# CEC1712H_S2_SX register map
Vendor: Microchip
Registers are 32-bit, read-write, reset 0x0 unless marked. A register's access mark holds for its fields unless they carry their own. Addresses are absolute, and some are shared; only a register's first bit layout is shown; [hi:lo] are bit positions; {n}, {i} and the like mark numbered series; 'fields as' and 'values as' point back to an identical list.

## GPIO
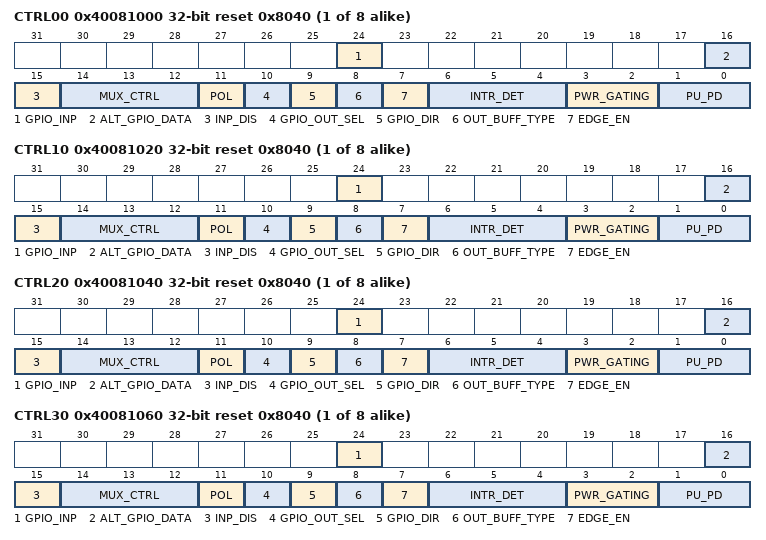
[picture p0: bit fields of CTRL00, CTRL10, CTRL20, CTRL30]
{0x40081000+4i} CTRL{i:02} reset 0x8040 (i=0..7)
  [24] GPIO_INP — GPIO input from pin, independent of the Mux selection for the pin or the Direction.
  [16] ALT_GPIO_DATA — GPIO Alternate Data Register.
  [15] INP_DIS — GPIO input disable
  [14:12] MUX_CTRL — 00 = GPIO Function, 01 = Function 1, 10 = Function 2, 11 = Function 3.
  [11] POL — 1=Inverted; 0=Non-inverted
  [10] GPIO_OUT_SEL — GPIO outputs registe select.0=GPIO ALTERNATE_GPIO_DATA 1=GPIO Output Register.
  [9] GPIO_DIR — Buffer direction when GPIO selected by pin mux 0 = Input, 1 = Output
  [8] OUT_BUFF_TYPE — 0 = Push-Pull, 1 = Open Drain
  [7] EDGE_EN — Determines the interrupt capability of the GPIO input.
  [6:4] INTR_DET — Determines the interrupt capability of the GPIO input.
  [3:2] PWR_GATING — The GPIO pin will be tristated when the selected power well is off.
  [1:0] PU_PD — These bits are used to enable an internal pull-up or pull-down resistor.
{0x40080FF8+4i} CTRL{i} reset 0x8040 (i=10..17)
  fields as CTRL00
{0x40080FF0+4i} CTRL{i} reset 0x8040 (i=20..27)
  fields as CTRL00
{0x40080FE8+4i} CTRL{i} reset 0x8040 (i=30..37)
  fields as CTRL00
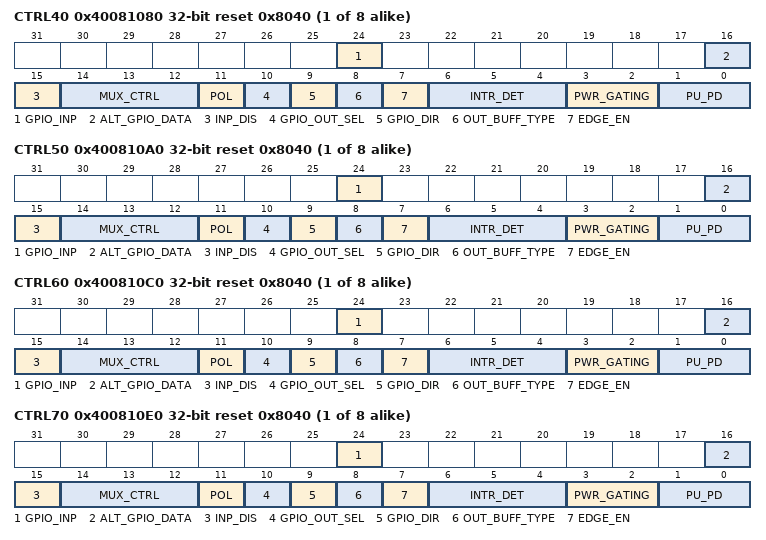
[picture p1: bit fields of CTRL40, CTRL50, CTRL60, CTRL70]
{0x40080FE0+4i} CTRL{i} reset 0x8040 (i=40..47)
  fields as CTRL00
{0x40080FD8+4i} CTRL{i} reset 0x8040 (i=50..57)
  fields as CTRL00
{0x40080FD0+4i} CTRL{i} reset 0x8040 (i=60..67)
  fields as CTRL00
{0x40080FC8+4i} CTRL{i} reset 0x8040 (i=70..77)
  fields as CTRL00
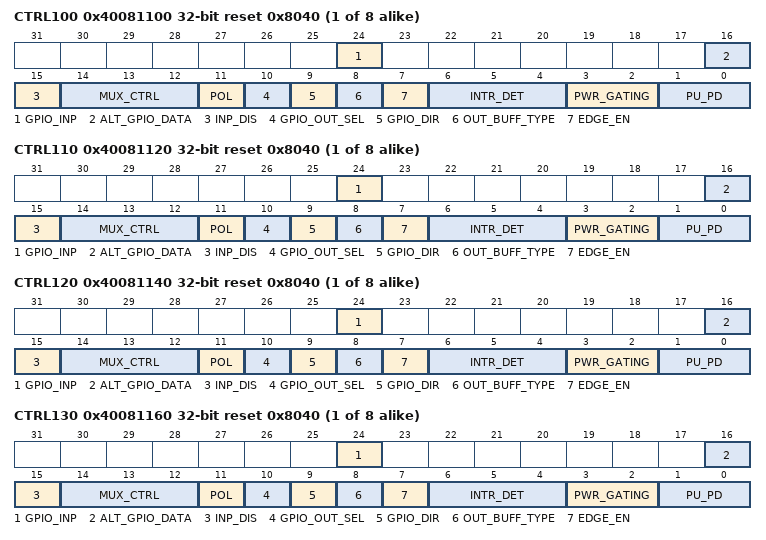
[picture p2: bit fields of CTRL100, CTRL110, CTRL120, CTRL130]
{0x40080F70+4i} CTRL{i} reset 0x8040 (i=100..107)
  fields as CTRL00
{0x40080F68+4i} CTRL{i} reset 0x8040 (i=110..117)
  fields as CTRL00
{0x40080F60+4i} CTRL{i} reset 0x8040 (i=120..127)
  fields as CTRL00
{0x40080F58+4i} CTRL{i} reset 0x8040 (i=130..137)
  fields as CTRL00
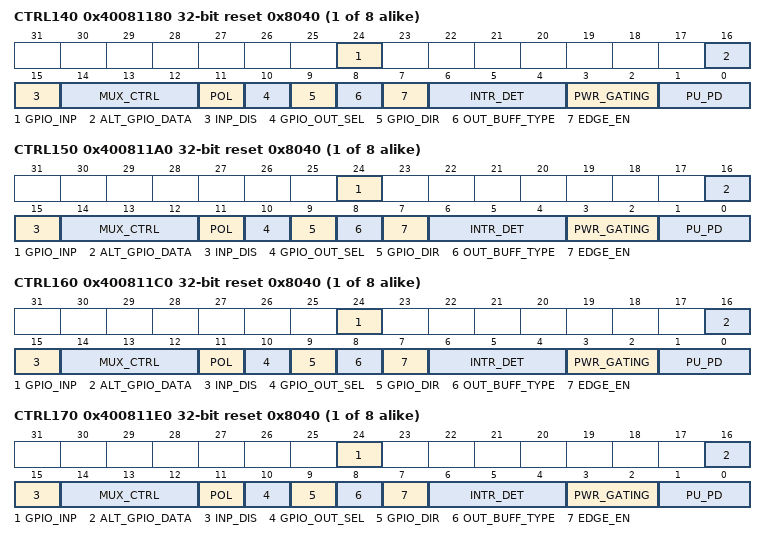
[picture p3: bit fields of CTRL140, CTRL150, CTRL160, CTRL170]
{0x40080F50+4i} CTRL{i} reset 0x8040 (i=140..147)
  fields as CTRL00
{0x40080F48+4i} CTRL{i} reset 0x8040 (i=150..157)
  fields as CTRL00
{0x40080F40+4i} CTRL{i} reset 0x8040 (i=160..167)
  fields as CTRL00
{0x40080F38+4i} CTRL{i} reset 0x8040 (i=170..177)
  fields as CTRL00
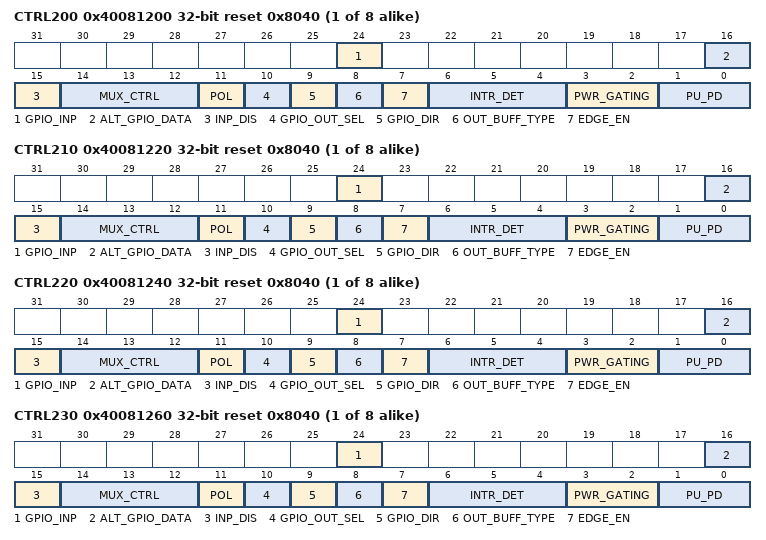
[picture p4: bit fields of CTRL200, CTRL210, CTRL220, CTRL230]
{0x40080EE0+4i} CTRL{i} reset 0x8040 (i=200..207)
  fields as CTRL00
{0x40080ED8+4i} CTRL{i} reset 0x8040 (i=210..217)
  fields as CTRL00
{0x40080ED0+4i} CTRL{i} reset 0x8040 (i=220..227)
  fields as CTRL00
{0x40080EC8+4i} CTRL{i} reset 0x8040 (i=230..237)
  fields as CTRL00
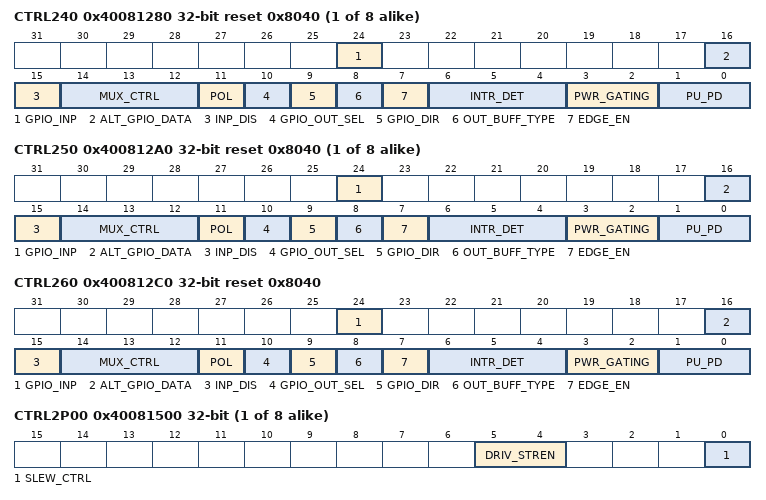
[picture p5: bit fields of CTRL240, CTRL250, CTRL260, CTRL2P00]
{0x40080EC0+4i} CTRL{i} reset 0x8040 (i=240..247)
  fields as CTRL00
{0x40080EB8+4i} CTRL{i} reset 0x8040 (i=250..257)
  fields as CTRL00
0x400812C0 CTRL260 reset 0x8040
  fields as CTRL00
{0x40081300+4i} PARIN{i} (i=0..5)
{0x40081380+4i} PAROUT{i} (i=0..5)
{0x40081500+4i} CTRL2P{i:02} (i=0..7)
  [5:4] DRIV_STREN — Selects the drive strength on the pin. 00 = 2mA, 01 = 4mA, 10 = 8mA, 11 = 12mA
  [0] SLEW_CTRL — Selects slew rate on the pin. 1=fast 0=slow
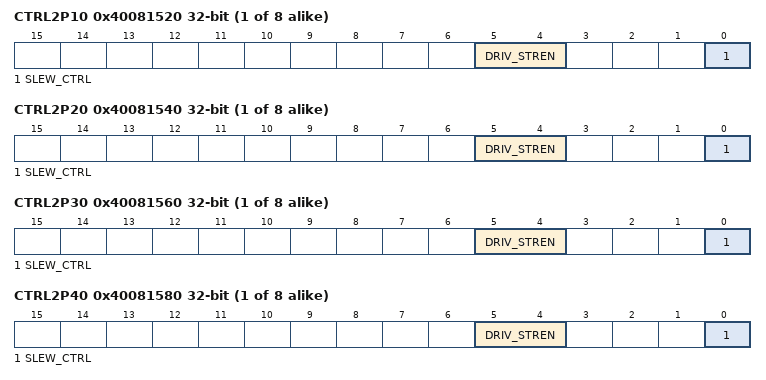
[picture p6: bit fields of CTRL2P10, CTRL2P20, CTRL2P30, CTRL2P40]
{0x400814F8+4i} CTRL2P{i} (i=10..17)
  fields as CTRL2P00
{0x400814F0+4i} CTRL2P{i} (i=20..27)
  fields as CTRL2P00
{0x400814E8+4i} CTRL2P{i} (i=30..37)
  fields as CTRL2P00
{0x400814E0+4i} CTRL2P{i} (i=40..47)
  fields as CTRL2P00
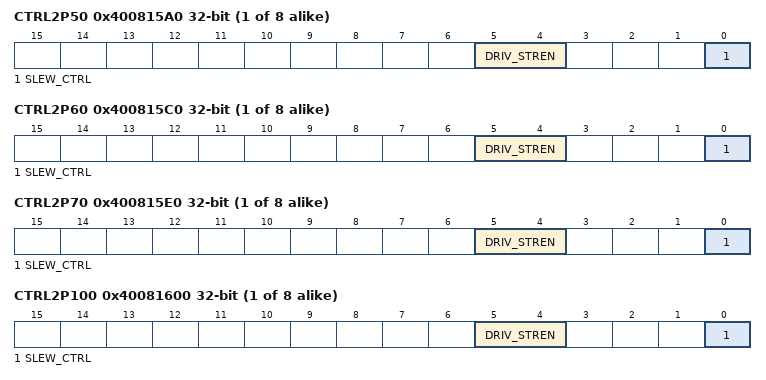
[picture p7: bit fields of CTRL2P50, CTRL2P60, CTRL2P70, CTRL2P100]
{0x400814D8+4i} CTRL2P{i} (i=50..57)
  fields as CTRL2P00
{0x400814D0+4i} CTRL2P{i} (i=60..67)
  fields as CTRL2P00
{0x400814C8+4i} CTRL2P{i} (i=70..77)
  fields as CTRL2P00
{0x40081470+4i} CTRL2P{i} (i=100..107)
  fields as CTRL2P00
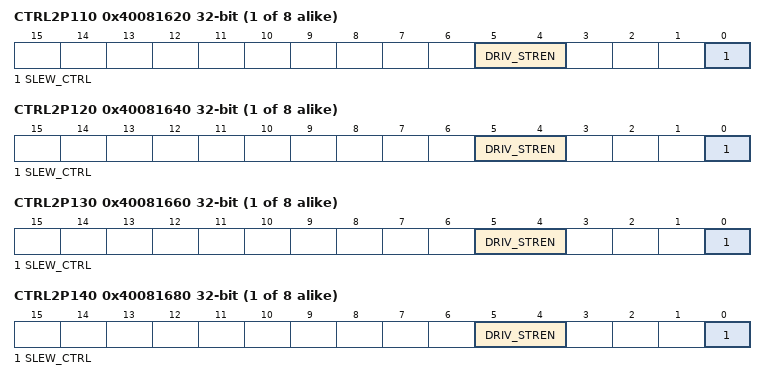
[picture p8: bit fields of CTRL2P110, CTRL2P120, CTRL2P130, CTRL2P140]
{0x40081468+4i} CTRL2P{i} (i=110..117)
  fields as CTRL2P00
{0x40081460+4i} CTRL2P{i} (i=120..127)
  fields as CTRL2P00
{0x40081458+4i} CTRL2P{i} (i=130..137)
  fields as CTRL2P00
{0x40081450+4i} CTRL2P{i} (i=140..147)
  fields as CTRL2P00
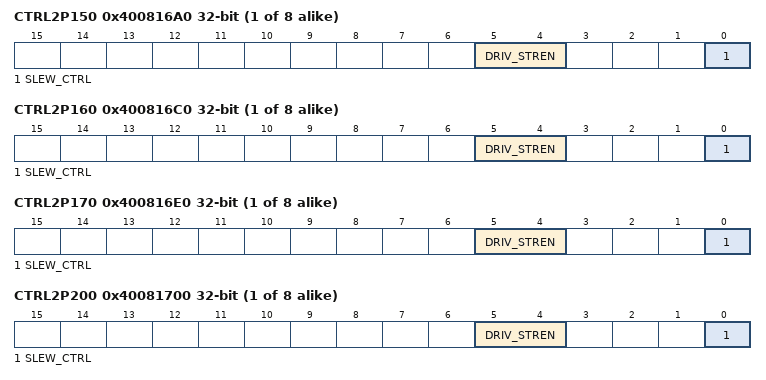
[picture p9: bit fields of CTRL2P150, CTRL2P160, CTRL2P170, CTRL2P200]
{0x40081448+4i} CTRL2P{i} (i=150..157)
  fields as CTRL2P00
{0x40081440+4i} CTRL2P{i} (i=160..167)
  fields as CTRL2P00
{0x40081438+4i} CTRL2P{i} (i=170..177)
  fields as CTRL2P00
{0x400813E0+4i} CTRL2P{i} (i=200..207)
  fields as CTRL2P00
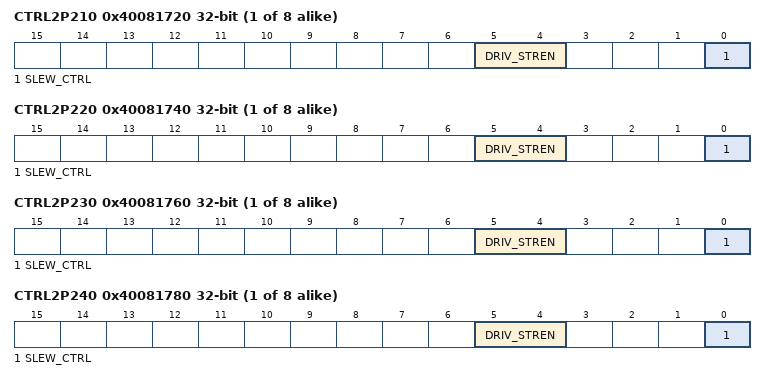
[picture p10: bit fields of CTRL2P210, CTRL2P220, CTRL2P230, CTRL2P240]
{0x400813D8+4i} CTRL2P{i} (i=210..217)
  fields as CTRL2P00
{0x400813D0+4i} CTRL2P{i} (i=220..227)
  fields as CTRL2P00
{0x400813C8+4i} CTRL2P{i} (i=230..237)
  fields as CTRL2P00
{0x400813C0+4i} CTRL2P{i} (i=240..247)
  fields as CTRL2P00
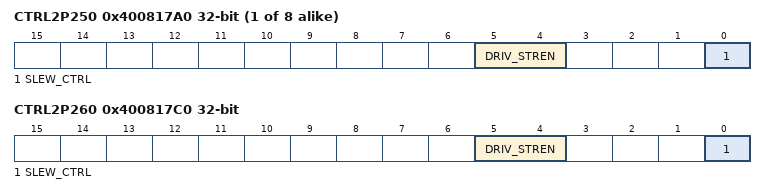
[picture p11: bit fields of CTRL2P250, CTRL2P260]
{0x400813B8+4i} CTRL2P{i} (i=250..257)
  fields as CTRL2P00
0x400817C0 CTRL2P260
  fields as CTRL2P00
